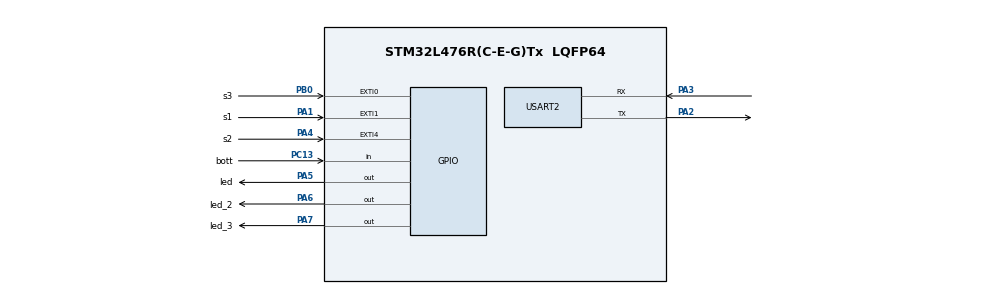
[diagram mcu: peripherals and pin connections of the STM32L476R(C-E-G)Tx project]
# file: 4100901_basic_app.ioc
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Mcu.Family=STM32L4
Mcu.Name=STM32L476R(C-E-G)Tx
Mcu.Package=LQFP64
NVIC.EXTI1_IRQn=true\:0\:0\:false\:false\:true\:true\:true\:true
NVIC.PriorityGroup=NVIC_PRIORITYGROUP_4
PA1.GPIO_Label=s1
PA1.GPIO_ModeDefaultEXTI=GPIO_MODE_IT_FALLING
PA1.Signal=GPXTI1
PA2.Mode=Asynchronous
PA2.Signal=USART2_TX
PA3.Mode=Asynchronous
PA3.Signal=USART2_RX
PA4.GPIO_Label=s2
PA4.GPIO_ModeDefaultEXTI=GPIO_MODE_IT_FALLING
PA4.Signal=GPXTI4
PA5.GPIO_Label=led 
PA5.Signal=GPIO_Output
PA6.GPIO_Label=led_2
PA6.Signal=GPIO_Output
PA7.GPIO_Label=led_3
PA7.Signal=GPIO_Output
PB0.GPIO_Label=s3
PB0.GPIO_ModeDefaultEXTI=GPIO_MODE_IT_FALLING
PB0.Signal=GPXTI0
PC13.GPIO_Label=bott
PC13.Signal=GPIO_Input
ProjectManager.HeapSize=0x200
ProjectManager.StackSize=0x400
ProjectManager.TargetToolchain=STM32CubeIDE
RCC.HSE_VALUE=8000000
RCC.HSI_VALUE=16000000
RCC.LSE_VALUE=32768
RCC.MSI_VALUE=4000000
RCC.VCOOutputFreq_Value=32000000
USART2.VirtualMode-Asynchronous=VM_ASYNC
board=custom

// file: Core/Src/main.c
/* USER CODE BEGIN Header */
/**
  ******************************************************************************
  * @file           : main.c
  * @brief          : Main program body
  ******************************************************************************
  * @attention
  *
  * Copyright (c) 2024 STMicroelectronics.
  * All rights reserved.
  *
  * This software is licensed under terms that can be found in the LICENSE file
  * in the root directory of this software component.
  * If no LICENSE file comes with this software, it is provided AS-IS.
  *
  ******************************************************************************
  */
/* USER CODE END Header */
#include "main.h"

UART_HandleTypeDef huart2;

void SystemClock_Config(void);
static void MX_GPIO_Init(void);
static void MX_USART2_UART_Init(void);

/* USER CODE BEGIN 0 */
void HAL_GPIO_EXTI_Callback(uint16_t GPIO_Pin)
{
	//UNUSED(GPIO_Pin);

	if (HAL_GPIO_ReadPin(GPIOC, GPIO_PIN_13)== 0) {
		HAL_GPIO_TogglePin(led_GPIO_Port, led_Pin);
		HAL_UART_Transmit(&huart2, "PB1\r\n", 5, 10);
	} else if (GPIO_Pin == GPIO_PIN_1) {
		HAL_GPIO_WritePin(led_GPIO_Port, led_Pin, 0);
		//for (uint16_t counter = 0; counter < 0xEFFF; counter++)
		//HAL_GPIO_WritePin (led_GPIO_Port, led_Pin, 1);
	}
}

/* USER CODE END 0 */

int main(void)
{

  /* MCU Configuration--------------------------------------------------------*/

  /* Reset of all peripherals, Initializes the Flash interface and the Systick. */
  HAL_Init();

  /* Configure the system clock */
  SystemClock_Config();

  /* Initialize all configured peripherals */
  MX_GPIO_Init();
  MX_USART2_UART_Init();
  /* USER CODE BEGIN 2 */
  HAL_UART_Transmit(&huart2, "Hello Word\r\n", 12 , 10);
  /* USER CODE END 2 */

  /* Infinite loop */
  /* USER CODE BEGIN WHILE */
  //uint32_t timeout_tick;
  while (1)
  {
	  if (HAL_GPIO_ReadPin(GPIOA, GPIO_PIN_1)== 0){
		  if (HAL_GPIO_ReadPin(GPIOA, GPIO_PIN_2)== 0){
			  HAL_GPIO_WritePin(GPIOA, GPIO_PIN_6, 0);
			  HAL_GPIO_WritePin(GPIOA, GPIO_PIN_5, 0);

	  } else { HAL_GPIO_WritePin(GPIOA, GPIO_PIN_5, 1);

	  }
	  //if (timeout_tick < HAL_GetTick()){
		//  timeout_tick = HAL_GetTick () + 500;
		  //GPIOA->ODR ^= 0x01 << 5;

    /* USER CODE END WHILE */

  }
}
}

void SystemClock_Config(void)
{
  RCC_OscInitTypeDef RCC_OscInitStruct = {0};
  RCC_ClkInitTypeDef RCC_ClkInitStruct = {0};

  /** Configure the main internal regulator output voltage
  */
  if (HAL_PWREx_ControlVoltageScaling(PWR_REGULATOR_VOLTAGE_SCALE1) != HAL_OK)
  {
    Error_Handler();
  }

  /** Initializes the RCC Oscillators according to the specified parameters
  * in the RCC_OscInitTypeDef structure.
  */
  RCC_OscInitStruct.OscillatorType = RCC_OSCILLATORTYPE_MSI;
  RCC_OscInitStruct.MSIState = RCC_MSI_ON;
  RCC_OscInitStruct.MSICalibrationValue = 0;
  RCC_OscInitStruct.MSIClockRange = RCC_MSIRANGE_6;
  RCC_OscInitStruct.PLL.PLLState = RCC_PLL_NONE;
  if (HAL_RCC_OscConfig(&RCC_OscInitStruct) != HAL_OK)
  {
    Error_Handler();
  }

  /** Initializes the CPU, AHB and APB buses clocks
  */
  RCC_ClkInitStruct.ClockType = RCC_CLOCKTYPE_HCLK|RCC_CLOCKTYPE_SYSCLK
                              |RCC_CLOCKTYPE_PCLK1|RCC_CLOCKTYPE_PCLK2;
  RCC_ClkInitStruct.SYSCLKSource = RCC_SYSCLKSOURCE_MSI;
  RCC_ClkInitStruct.AHBCLKDivider = RCC_SYSCLK_DIV1;
  RCC_ClkInitStruct.APB1CLKDivider = RCC_HCLK_DIV1;
  RCC_ClkInitStruct.APB2CLKDivider = RCC_HCLK_DIV1;

  if (HAL_RCC_ClockConfig(&RCC_ClkInitStruct, FLASH_LATENCY_0) != HAL_OK)
  {
    Error_Handler();
  }
}

static void MX_USART2_UART_Init(void)
{

  huart2.Instance = USART2;
  huart2.Init.BaudRate = 115200;
  huart2.Init.WordLength = UART_WORDLENGTH_8B;
  huart2.Init.StopBits = UART_STOPBITS_1;
  huart2.Init.Parity = UART_PARITY_NONE;
  huart2.Init.Mode = UART_MODE_TX_RX;
  huart2.Init.HwFlowCtl = UART_HWCONTROL_NONE;
  huart2.Init.OverSampling = UART_OVERSAMPLING_16;
  huart2.Init.OneBitSampling = UART_ONE_BIT_SAMPLE_DISABLE;
  huart2.AdvancedInit.AdvFeatureInit = UART_ADVFEATURE_NO_INIT;
  if (HAL_UART_Init(&huart2) != HAL_OK)
  {
    Error_Handler();
  }

}

static void MX_GPIO_Init(void)
{
  GPIO_InitTypeDef GPIO_InitStruct = {0};

  /* GPIO Ports Clock Enable */
  __HAL_RCC_GPIOC_CLK_ENABLE();
  __HAL_RCC_GPIOA_CLK_ENABLE();
  __HAL_RCC_GPIOB_CLK_ENABLE();

  /*Configure GPIO pin Output Level */
  HAL_GPIO_WritePin(GPIOA, led_Pin|led_2_Pin|led_3_Pin, GPIO_PIN_RESET);

  /*Configure GPIO pin : bott_Pin */
  GPIO_InitStruct.Pin = bott_Pin;
  GPIO_InitStruct.Mode = GPIO_MODE_INPUT;
  GPIO_InitStruct.Pull = GPIO_NOPULL;
  HAL_GPIO_Init(bott_GPIO_Port, &GPIO_InitStruct);

  /*Configure GPIO pins : s1_Pin s2_Pin */
  GPIO_InitStruct.Pin = s1_Pin|s2_Pin;
  GPIO_InitStruct.Mode = GPIO_MODE_IT_FALLING;
  GPIO_InitStruct.Pull = GPIO_NOPULL;
  HAL_GPIO_Init(GPIOA, &GPIO_InitStruct);

  /*Configure GPIO pins : led_Pin led_2_Pin led_3_Pin */
  GPIO_InitStruct.Pin = led_Pin|led_2_Pin|led_3_Pin;
  GPIO_InitStruct.Mode = GPIO_MODE_OUTPUT_PP;
  GPIO_InitStruct.Pull = GPIO_NOPULL;
  GPIO_InitStruct.Speed = GPIO_SPEED_FREQ_LOW;
  HAL_GPIO_Init(GPIOA, &GPIO_InitStruct);

  /*Configure GPIO pin : s3_Pin */
  GPIO_InitStruct.Pin = s3_Pin;
  GPIO_InitStruct.Mode = GPIO_MODE_IT_FALLING;
  GPIO_InitStruct.Pull = GPIO_NOPULL;
  HAL_GPIO_Init(s3_GPIO_Port, &GPIO_InitStruct);

  /* EXTI interrupt init*/
  HAL_NVIC_SetPriority(EXTI1_IRQn, 0, 0);
  HAL_NVIC_EnableIRQ(EXTI1_IRQn);

}

void Error_Handler(void)
{
  __disable_irq();
  while (1)
  {
  }
}
